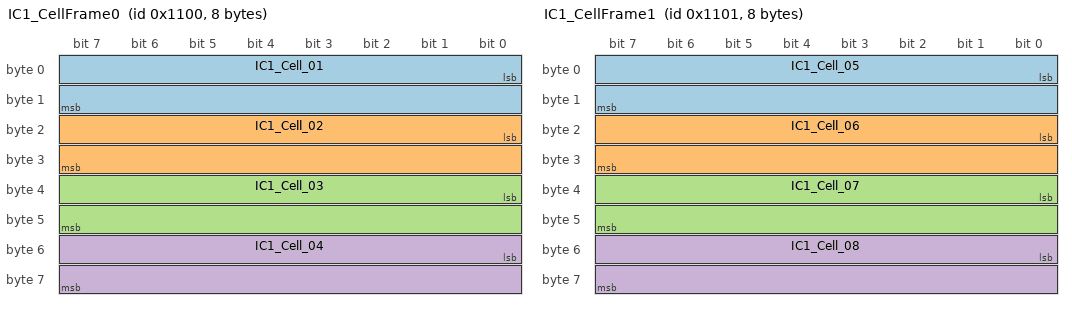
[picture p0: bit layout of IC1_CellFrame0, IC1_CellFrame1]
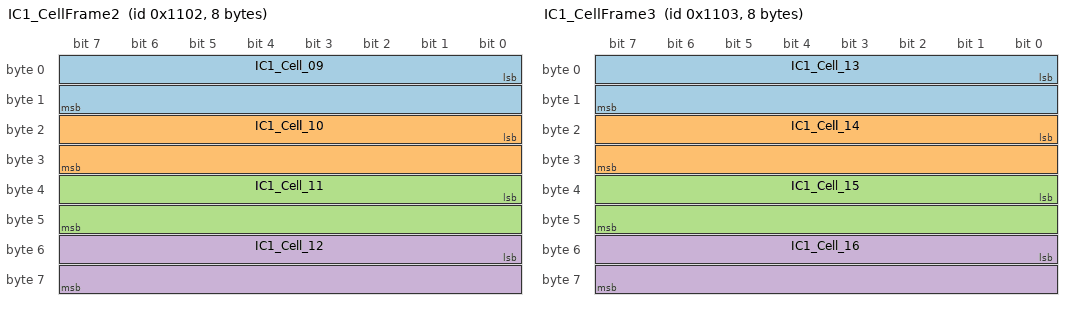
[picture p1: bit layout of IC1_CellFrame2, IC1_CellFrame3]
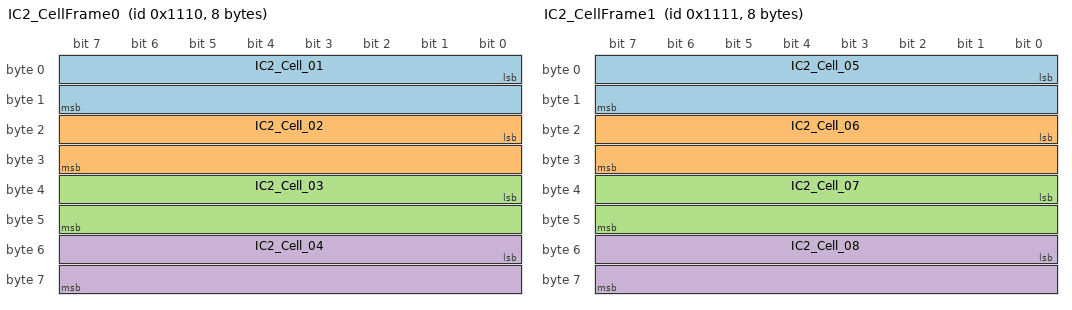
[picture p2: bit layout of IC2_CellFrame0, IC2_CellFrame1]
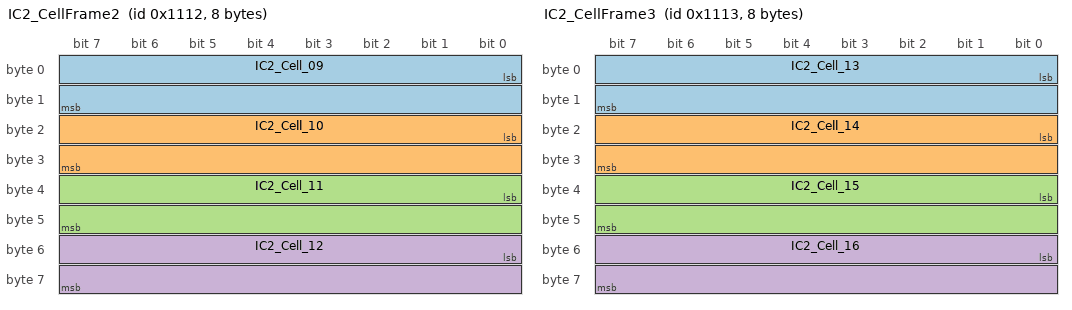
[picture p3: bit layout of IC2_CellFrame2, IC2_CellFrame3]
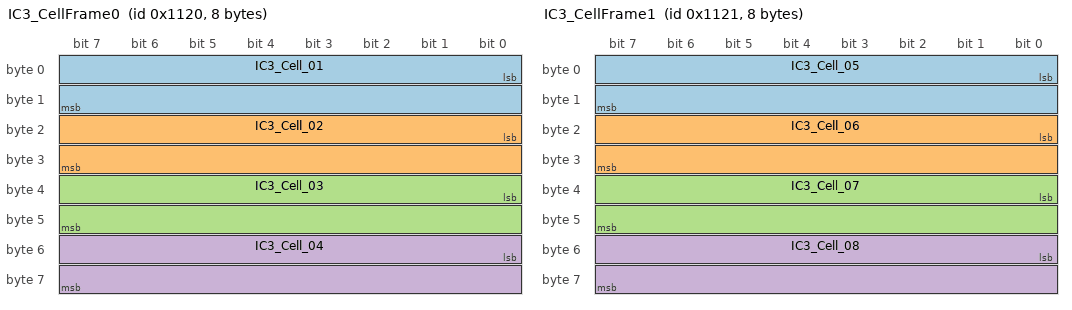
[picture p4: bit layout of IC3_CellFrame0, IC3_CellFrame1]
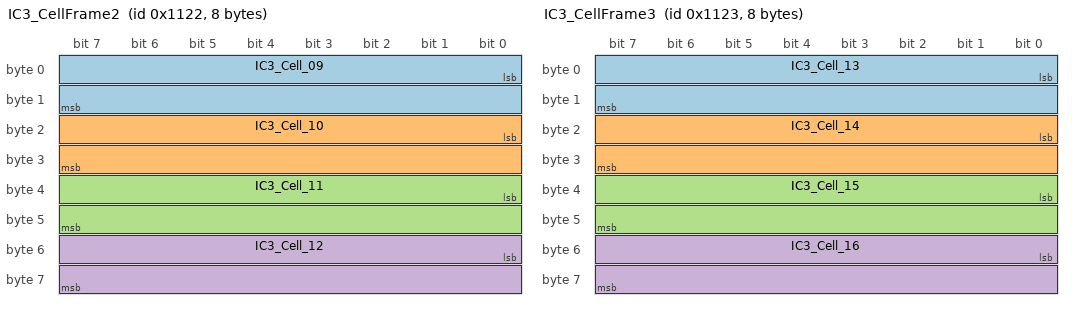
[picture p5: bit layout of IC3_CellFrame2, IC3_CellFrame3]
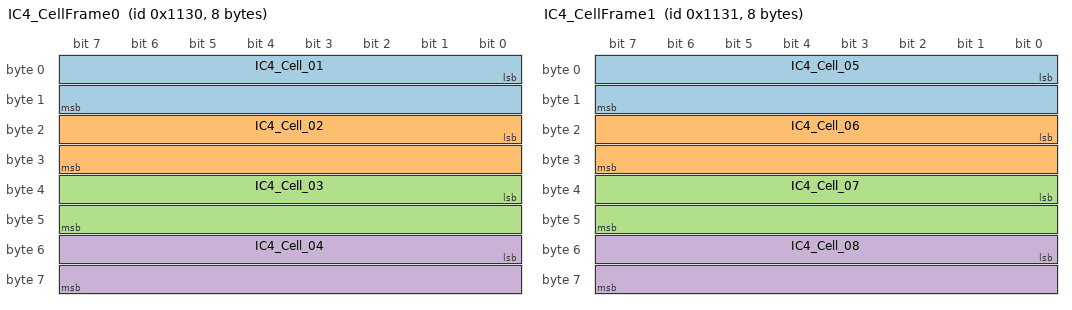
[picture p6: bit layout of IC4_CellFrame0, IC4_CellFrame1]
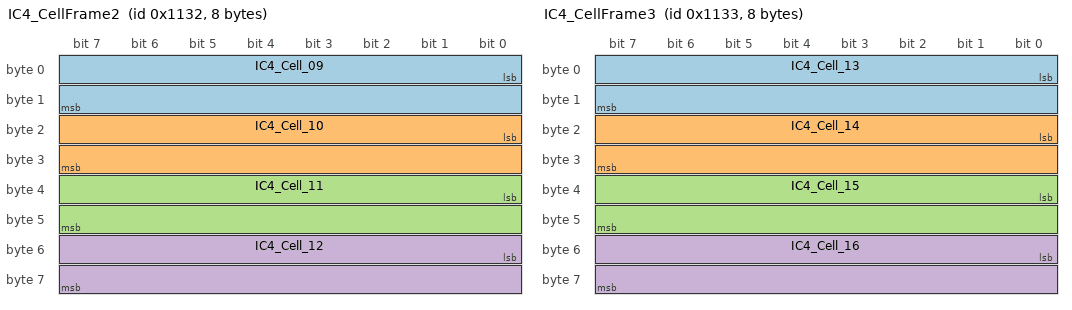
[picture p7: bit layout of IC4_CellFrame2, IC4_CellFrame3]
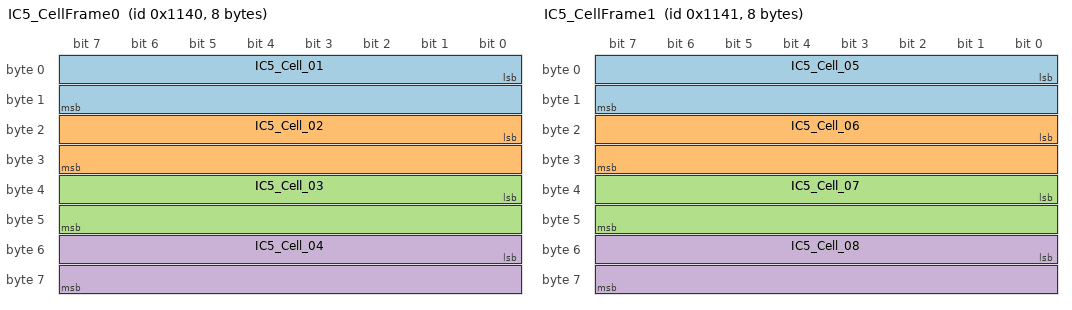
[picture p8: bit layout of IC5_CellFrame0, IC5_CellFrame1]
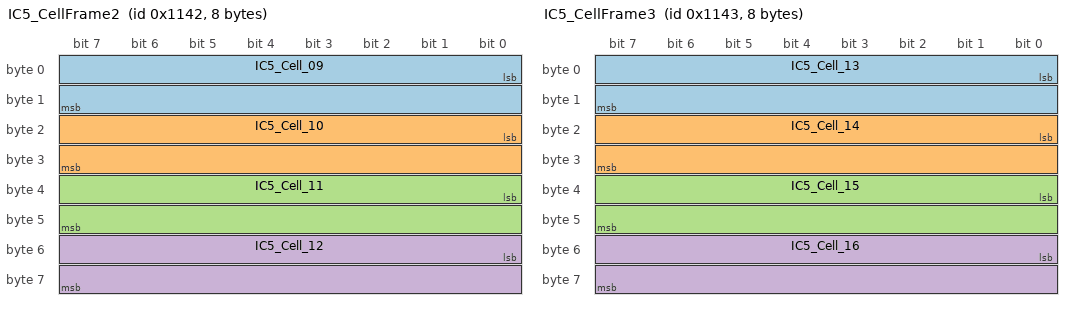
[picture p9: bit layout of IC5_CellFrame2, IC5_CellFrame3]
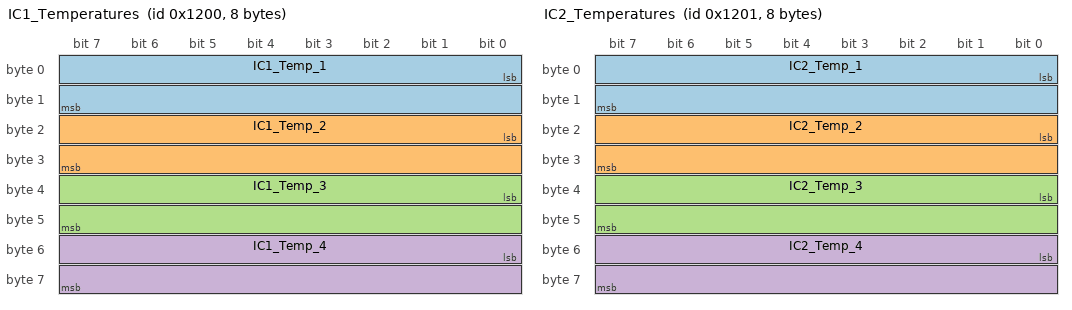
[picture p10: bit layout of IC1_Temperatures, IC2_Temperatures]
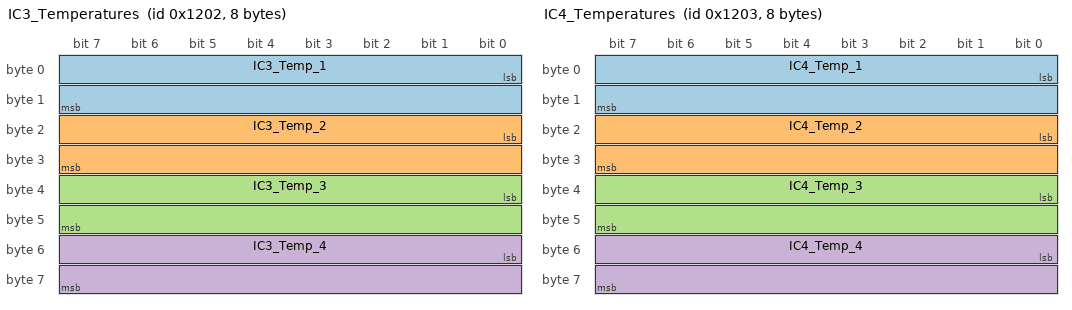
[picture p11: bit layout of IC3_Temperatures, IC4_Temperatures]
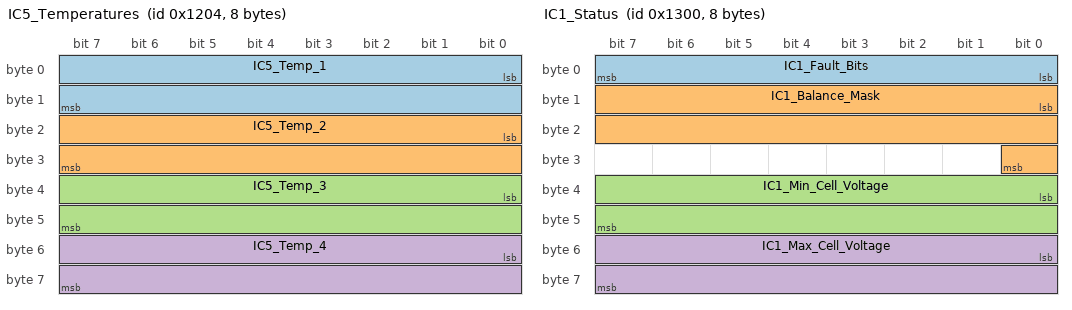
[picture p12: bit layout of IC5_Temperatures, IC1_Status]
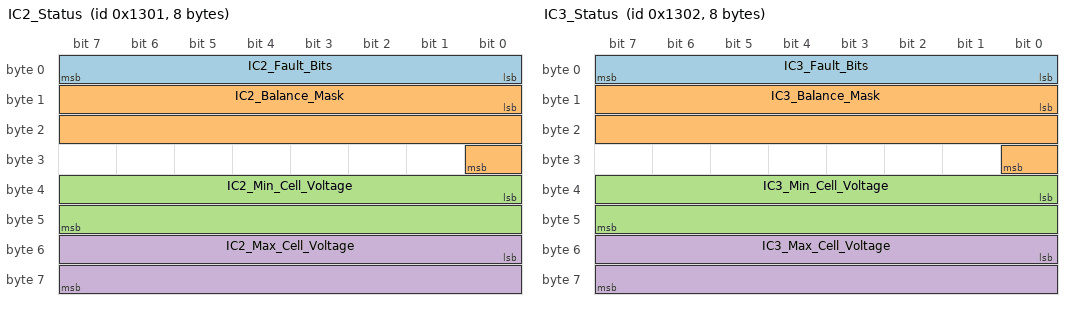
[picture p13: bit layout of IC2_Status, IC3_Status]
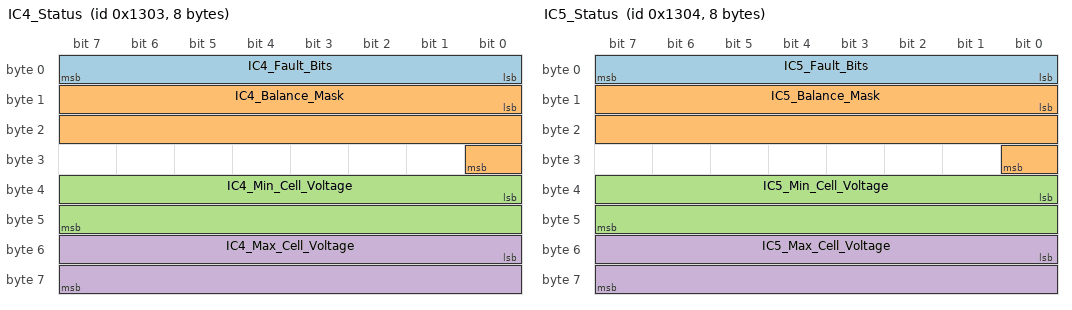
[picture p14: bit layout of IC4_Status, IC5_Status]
VERSION ""

NS_ :

BS_:

BU_: BMS Host

BO_ 0x1100 IC1_CellFrame0: 8 BMS
 SG_ IC1_Cell_01 : 0|16@1+ (0.0001,0) [0|6.5535] "V" Host
 SG_ IC1_Cell_02 : 16|16@1+ (0.0001,0) [0|6.5535] "V" Host
 SG_ IC1_Cell_03 : 32|16@1+ (0.0001,0) [0|6.5535] "V" Host
 SG_ IC1_Cell_04 : 48|16@1+ (0.0001,0) [0|6.5535] "V" Host

BO_ 0x1101 IC1_CellFrame1: 8 BMS
 SG_ IC1_Cell_05 : 0|16@1+ (0.0001,0) [0|6.5535] "V" Host
 SG_ IC1_Cell_06 : 16|16@1+ (0.0001,0) [0|6.5535] "V" Host
 SG_ IC1_Cell_07 : 32|16@1+ (0.0001,0) [0|6.5535] "V" Host
 SG_ IC1_Cell_08 : 48|16@1+ (0.0001,0) [0|6.5535] "V" Host

BO_ 0x1102 IC1_CellFrame2: 8 BMS
 SG_ IC1_Cell_09 : 0|16@1+ (0.0001,0) [0|6.5535] "V" Host
 SG_ IC1_Cell_10 : 16|16@1+ (0.0001,0) [0|6.5535] "V" Host
 SG_ IC1_Cell_11 : 32|16@1+ (0.0001,0) [0|6.5535] "V" Host
 SG_ IC1_Cell_12 : 48|16@1+ (0.0001,0) [0|6.5535] "V" Host

BO_ 0x1103 IC1_CellFrame3: 8 BMS
 SG_ IC1_Cell_13 : 0|16@1+ (0.0001,0) [0|6.5535] "V" Host
 SG_ IC1_Cell_14 : 16|16@1+ (0.0001,0) [0|6.5535] "V" Host
 SG_ IC1_Cell_15 : 32|16@1+ (0.0001,0) [0|6.5535] "V" Host
 SG_ IC1_Cell_16 : 48|16@1+ (0.0001,0) [0|6.5535] "V" Host

BO_ 0x1104 IC1_CellFrame4: 8 BMS
 SG_ IC1_Cell_17 : 0|16@1+ (0.0001,0) [0|6.5535] "V" Host

BO_ 0x1110 IC2_CellFrame0: 8 BMS
 SG_ IC2_Cell_01 : 0|16@1+ (0.0001,0) [0|6.5535] "V" Host
 SG_ IC2_Cell_02 : 16|16@1+ (0.0001,0) [0|6.5535] "V" Host
 SG_ IC2_Cell_03 : 32|16@1+ (0.0001,0) [0|6.5535] "V" Host
 SG_ IC2_Cell_04 : 48|16@1+ (0.0001,0) [0|6.5535] "V" Host

BO_ 0x1111 IC2_CellFrame1: 8 BMS
 SG_ IC2_Cell_05 : 0|16@1+ (0.0001,0) [0|6.5535] "V" Host
 SG_ IC2_Cell_06 : 16|16@1+ (0.0001,0) [0|6.5535] "V" Host
 SG_ IC2_Cell_07 : 32|16@1+ (0.0001,0) [0|6.5535] "V" Host
 SG_ IC2_Cell_08 : 48|16@1+ (0.0001,0) [0|6.5535] "V" Host

BO_ 0x1112 IC2_CellFrame2: 8 BMS
 SG_ IC2_Cell_09 : 0|16@1+ (0.0001,0) [0|6.5535] "V" Host
 SG_ IC2_Cell_10 : 16|16@1+ (0.0001,0) [0|6.5535] "V" Host
 SG_ IC2_Cell_11 : 32|16@1+ (0.0001,0) [0|6.5535] "V" Host
 SG_ IC2_Cell_12 : 48|16@1+ (0.0001,0) [0|6.5535] "V" Host

BO_ 0x1113 IC2_CellFrame3: 8 BMS
 SG_ IC2_Cell_13 : 0|16@1+ (0.0001,0) [0|6.5535] "V" Host
 SG_ IC2_Cell_14 : 16|16@1+ (0.0001,0) [0|6.5535] "V" Host
 SG_ IC2_Cell_15 : 32|16@1+ (0.0001,0) [0|6.5535] "V" Host
 SG_ IC2_Cell_16 : 48|16@1+ (0.0001,0) [0|6.5535] "V" Host

BO_ 0x1114 IC2_CellFrame4: 8 BMS
 SG_ IC2_Cell_17 : 0|16@1+ (0.0001,0) [0|6.5535] "V" Host

BO_ 0x1120 IC3_CellFrame0: 8 BMS
 SG_ IC3_Cell_01 : 0|16@1+ (0.0001,0) [0|6.5535] "V" Host
 SG_ IC3_Cell_02 : 16|16@1+ (0.0001,0) [0|6.5535] "V" Host
 SG_ IC3_Cell_03 : 32|16@1+ (0.0001,0) [0|6.5535] "V" Host
 SG_ IC3_Cell_04 : 48|16@1+ (0.0001,0) [0|6.5535] "V" Host

BO_ 0x1121 IC3_CellFrame1: 8 BMS
 SG_ IC3_Cell_05 : 0|16@1+ (0.0001,0) [0|6.5535] "V" Host
 SG_ IC3_Cell_06 : 16|16@1+ (0.0001,0) [0|6.5535] "V" Host
 SG_ IC3_Cell_07 : 32|16@1+ (0.0001,0) [0|6.5535] "V" Host
 SG_ IC3_Cell_08 : 48|16@1+ (0.0001,0) [0|6.5535] "V" Host

BO_ 0x1122 IC3_CellFrame2: 8 BMS
 SG_ IC3_Cell_09 : 0|16@1+ (0.0001,0) [0|6.5535] "V" Host
 SG_ IC3_Cell_10 : 16|16@1+ (0.0001,0) [0|6.5535] "V" Host
 SG_ IC3_Cell_11 : 32|16@1+ (0.0001,0) [0|6.5535] "V" Host
 SG_ IC3_Cell_12 : 48|16@1+ (0.0001,0) [0|6.5535] "V" Host

BO_ 0x1123 IC3_CellFrame3: 8 BMS
 SG_ IC3_Cell_13 : 0|16@1+ (0.0001,0) [0|6.5535] "V" Host
 SG_ IC3_Cell_14 : 16|16@1+ (0.0001,0) [0|6.5535] "V" Host
 SG_ IC3_Cell_15 : 32|16@1+ (0.0001,0) [0|6.5535] "V" Host
 SG_ IC3_Cell_16 : 48|16@1+ (0.0001,0) [0|6.5535] "V" Host

BO_ 0x1124 IC3_CellFrame4: 8 BMS
 SG_ IC3_Cell_17 : 0|16@1+ (0.0001,0) [0|6.5535] "V" Host

BO_ 0x1130 IC4_CellFrame0: 8 BMS
 SG_ IC4_Cell_01 : 0|16@1+ (0.0001,0) [0|6.5535] "V" Host
 SG_ IC4_Cell_02 : 16|16@1+ (0.0001,0) [0|6.5535] "V" Host
 SG_ IC4_Cell_03 : 32|16@1+ (0.0001,0) [0|6.5535] "V" Host
 SG_ IC4_Cell_04 : 48|16@1+ (0.0001,0) [0|6.5535] "V" Host

BO_ 0x1131 IC4_CellFrame1: 8 BMS
 SG_ IC4_Cell_05 : 0|16@1+ (0.0001,0) [0|6.5535] "V" Host
 SG_ IC4_Cell_06 : 16|16@1+ (0.0001,0) [0|6.5535] "V" Host
 SG_ IC4_Cell_07 : 32|16@1+ (0.0001,0) [0|6.5535] "V" Host
 SG_ IC4_Cell_08 : 48|16@1+ (0.0001,0) [0|6.5535] "V" Host

BO_ 0x1132 IC4_CellFrame2: 8 BMS
 SG_ IC4_Cell_09 : 0|16@1+ (0.0001,0) [0|6.5535] "V" Host
 SG_ IC4_Cell_10 : 16|16@1+ (0.0001,0) [0|6.5535] "V" Host
 SG_ IC4_Cell_11 : 32|16@1+ (0.0001,0) [0|6.5535] "V" Host
 SG_ IC4_Cell_12 : 48|16@1+ (0.0001,0) [0|6.5535] "V" Host

BO_ 0x1133 IC4_CellFrame3: 8 BMS
 SG_ IC4_Cell_13 : 0|16@1+ (0.0001,0) [0|6.5535] "V" Host
 SG_ IC4_Cell_14 : 16|16@1+ (0.0001,0) [0|6.5535] "V" Host
 SG_ IC4_Cell_15 : 32|16@1+ (0.0001,0) [0|6.5535] "V" Host
 SG_ IC4_Cell_16 : 48|16@1+ (0.0001,0) [0|6.5535] "V" Host

BO_ 0x1134 IC4_CellFrame4: 8 BMS
 SG_ IC4_Cell_17 : 0|16@1+ (0.0001,0) [0|6.5535] "V" Host

BO_ 0x1140 IC5_CellFrame0: 8 BMS
 SG_ IC5_Cell_01 : 0|16@1+ (0.0001,0) [0|6.5535] "V" Host
 SG_ IC5_Cell_02 : 16|16@1+ (0.0001,0) [0|6.5535] "V" Host
 SG_ IC5_Cell_03 : 32|16@1+ (0.0001,0) [0|6.5535] "V" Host
 SG_ IC5_Cell_04 : 48|16@1+ (0.0001,0) [0|6.5535] "V" Host

BO_ 0x1141 IC5_CellFrame1: 8 BMS
 SG_ IC5_Cell_05 : 0|16@1+ (0.0001,0) [0|6.5535] "V" Host
 SG_ IC5_Cell_06 : 16|16@1+ (0.0001,0) [0|6.5535] "V" Host
 SG_ IC5_Cell_07 : 32|16@1+ (0.0001,0) [0|6.5535] "V" Host
 SG_ IC5_Cell_08 : 48|16@1+ (0.0001,0) [0|6.5535] "V" Host

BO_ 0x1142 IC5_CellFrame2: 8 BMS
 SG_ IC5_Cell_09 : 0|16@1+ (0.0001,0) [0|6.5535] "V" Host
 SG_ IC5_Cell_10 : 16|16@1+ (0.0001,0) [0|6.5535] "V" Host
 SG_ IC5_Cell_11 : 32|16@1+ (0.0001,0) [0|6.5535] "V" Host
 SG_ IC5_Cell_12 : 48|16@1+ (0.0001,0) [0|6.5535] "V" Host

BO_ 0x1143 IC5_CellFrame3: 8 BMS
 SG_ IC5_Cell_13 : 0|16@1+ (0.0001,0) [0|6.5535] "V" Host
 SG_ IC5_Cell_14 : 16|16@1+ (0.0001,0) [0|6.5535] "V" Host
 SG_ IC5_Cell_15 : 32|16@1+ (0.0001,0) [0|6.5535] "V" Host
 SG_ IC5_Cell_16 : 48|16@1+ (0.0001,0) [0|6.5535] "V" Host

BO_ 0x1144 IC5_CellFrame4: 8 BMS
 SG_ IC5_Cell_17 : 0|16@1+ (0.0001,0) [0|6.5535] "V" Host

BO_ 0x1200 IC1_Temperatures: 8 BMS
 SG_ IC1_Temp_1 : 0|16@1- (0.1,0) [-3276.8|3276.7] "degC" Host
 SG_ IC1_Temp_2 : 16|16@1- (0.1,0) [-3276.8|3276.7] "degC" Host
 SG_ IC1_Temp_3 : 32|16@1- (0.1,0) [-3276.8|3276.7] "degC" Host
 SG_ IC1_Temp_4 : 48|16@1- (0.1,0) [-3276.8|3276.7] "degC" Host

BO_ 0x1201 IC2_Temperatures: 8 BMS
 SG_ IC2_Temp_1 : 0|16@1- (0.1,0) [-3276.8|3276.7] "degC" Host
 SG_ IC2_Temp_2 : 16|16@1- (0.1,0) [-3276.8|3276.7] "degC" Host
 SG_ IC2_Temp_3 : 32|16@1- (0.1,0) [-3276.8|3276.7] "degC" Host
 SG_ IC2_Temp_4 : 48|16@1- (0.1,0) [-3276.8|3276.7] "degC" Host

BO_ 0x1202 IC3_Temperatures: 8 BMS
 SG_ IC3_Temp_1 : 0|16@1- (0.1,0) [-3276.8|3276.7] "degC" Host
 SG_ IC3_Temp_2 : 16|16@1- (0.1,0) [-3276.8|3276.7] "degC" Host
 SG_ IC3_Temp_3 : 32|16@1- (0.1,0) [-3276.8|3276.7] "degC" Host
 SG_ IC3_Temp_4 : 48|16@1- (0.1,0) [-3276.8|3276.7] "degC" Host

BO_ 0x1203 IC4_Temperatures: 8 BMS
 SG_ IC4_Temp_1 : 0|16@1- (0.1,0) [-3276.8|3276.7] "degC" Host
 SG_ IC4_Temp_2 : 16|16@1- (0.1,0) [-3276.8|3276.7] "degC" Host
 SG_ IC4_Temp_3 : 32|16@1- (0.1,0) [-3276.8|3276.7] "degC" Host
 SG_ IC4_Temp_4 : 48|16@1- (0.1,0) [-3276.8|3276.7] "degC" Host

BO_ 0x1204 IC5_Temperatures: 8 BMS
 SG_ IC5_Temp_1 : 0|16@1- (0.1,0) [-3276.8|3276.7] "degC" Host
 SG_ IC5_Temp_2 : 16|16@1- (0.1,0) [-3276.8|3276.7] "degC" Host
 SG_ IC5_Temp_3 : 32|16@1- (0.1,0) [-3276.8|3276.7] "degC" Host
 SG_ IC5_Temp_4 : 48|16@1- (0.1,0) [-3276.8|3276.7] "degC" Host

BO_ 0x1300 IC1_Status: 8 BMS
 SG_ IC1_Fault_Bits : 0|8@1+ (1,0) [0|255] "" Host
 SG_ IC1_Balance_Mask : 8|17@1+ (1,0) [0|131071] "" Host
 SG_ IC1_Min_Cell_Voltage : 32|16@1+ (0.0001,0) [0|6.5535] "V" Host
 SG_ IC1_Max_Cell_Voltage : 48|16@1+ (0.0001,0) [0|6.5535] "V" Host

BO_ 0x1301 IC2_Status: 8 BMS
 SG_ IC2_Fault_Bits : 0|8@1+ (1,0) [0|255] "" Host
 SG_ IC2_Balance_Mask : 8|17@1+ (1,0) [0|131071] "" Host
 SG_ IC2_Min_Cell_Voltage : 32|16@1+ (0.0001,0) [0|6.5535] "V" Host
 SG_ IC2_Max_Cell_Voltage : 48|16@1+ (0.0001,0) [0|6.5535] "V" Host

BO_ 0x1302 IC3_Status: 8 BMS
 SG_ IC3_Fault_Bits : 0|8@1+ (1,0) [0|255] "" Host
 SG_ IC3_Balance_Mask : 8|17@1+ (1,0) [0|131071] "" Host
 SG_ IC3_Min_Cell_Voltage : 32|16@1+ (0.0001,0) [0|6.5535] "V" Host
 SG_ IC3_Max_Cell_Voltage : 48|16@1+ (0.0001,0) [0|6.5535] "V" Host

BO_ 0x1303 IC4_Status: 8 BMS
 SG_ IC4_Fault_Bits : 0|8@1+ (1,0) [0|255] "" Host
 SG_ IC4_Balance_Mask : 8|17@1+ (1,0) [0|131071] "" Host
 SG_ IC4_Min_Cell_Voltage : 32|16@1+ (0.0001,0) [0|6.5535] "V" Host
 SG_ IC4_Max_Cell_Voltage : 48|16@1+ (0.0001,0) [0|6.5535] "V" Host

BO_ 0x1304 IC5_Status: 8 BMS
 SG_ IC5_Fault_Bits : 0|8@1+ (1,0) [0|255] "" Host
 SG_ IC5_Balance_Mask : 8|17@1+ (1,0) [0|131071] "" Host
 SG_ IC5_Min_Cell_Voltage : 32|16@1+ (0.0001,0) [0|6.5535] "V" Host
 SG_ IC5_Max_Cell_Voltage : 48|16@1+ (0.0001,0) [0|6.5535] "V" Host

CM_ BO_ 0x1100 "IC1 Cells 1-4, 100uV/bit";
CM_ BO_ 0x1101 "IC1 Cells 5-8, 100uV/bit";
CM_ BO_ 0x1102 "IC1 Cells 9-12, 100uV/bit";
CM_ BO_ 0x1103 "IC1 Cells 13-16, 100uV/bit";
CM_ BO_ 0x1104 "IC1 Cell 17, 100uV/bit";

CM_ BO_ 0x1200 "IC1 Temperatures (NTC 1-4), 0.1 degC/bit";
CM_ BO_ 0x1300 "IC1 BMS Status (Faults, Balance, Min/Max Voltage)";

CM_ SG_ 0x1300 IC1_Fault_Bits "Bit 0: !BMS_OK, Bit 1: Temp Range ERR, Bit 2: Over Temp, Bit 3: Cell range ERR, Bit 4: Open Wire";
CM_ SG_ 0x1300 IC1_Balance_Mask "17-bit mask for cells being discharged";

BA_DEF_  "BusType" STRING ;
BA_DEF_DEF_  "BusType" "CAN";
